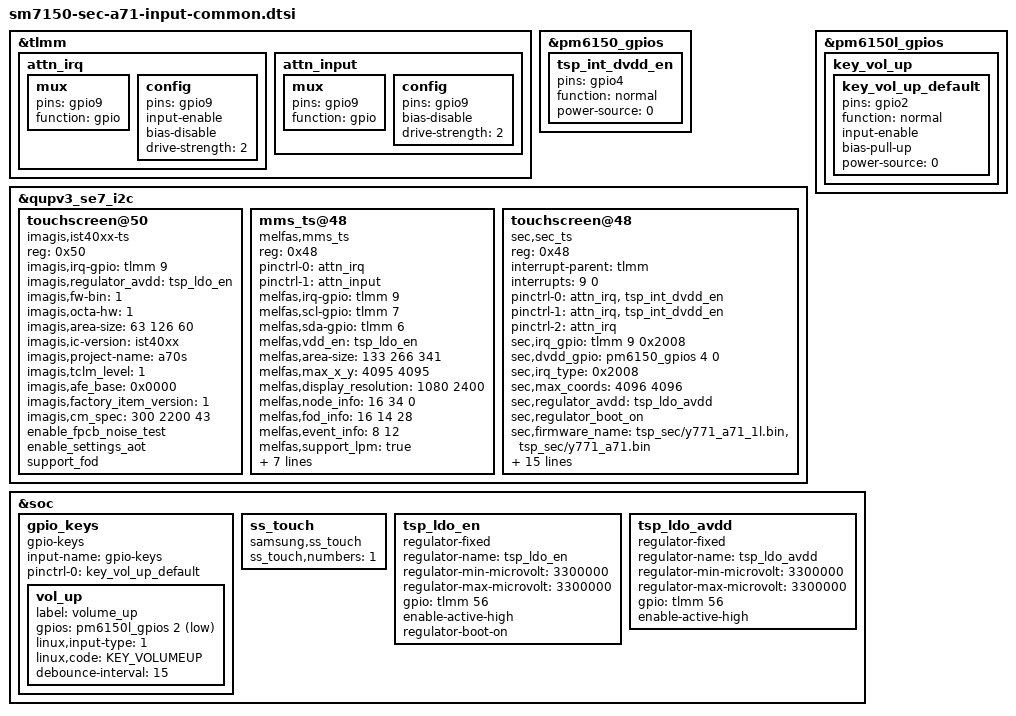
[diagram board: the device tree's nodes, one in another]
/* Copyright (c) 2016-2017, The Linux Foundation. All rights reserved.
 *
 * This program is free software; you can redistribute it and/or modify
 * it under the terms of the GNU General Public License version 2 and
 * only version 2 as published by the Free Software Foundation.
 *
 * This program is distributed in the hope that it will be useful,
 * but WITHOUT ANY WARRANTY; without even the implied warranty of
 * MERCHANTABILITY or FITNESS FOR A PARTICULAR PURPOSE.  See the
 * GNU General Public License for more details.
 */

#include <dt-bindings/input/input.h>

&tlmm {
   attn_irq: attn_irq {
		mux {
			pins = "gpio9";
			function = "gpio";
		};
		
		config {
			pins = "gpio9";
			input-enable;
			bias-disable; /* No PULL */
			drive-strength = <2>;
		};
	};	
	attn_input: attn_input {
		mux {
			pins = "gpio9";
			function = "gpio";
		};
		
		config {
			pins = "gpio9";
			/*input-enable;*/
			bias-disable;
			drive-strength = <2>;
		};
	};
};

&pm6150_gpios {
	tsp_int_dvdd_en: tsp_int_dvdd_en {
		pins = "gpio4";
		function = "normal";
		power-source = <0>;
	};
};


&qupv3_se7_i2c {
	status = "ok";

	touchscreen@50 {
		compatible = "imagis,ist40xx-ts";
		reg = <0x50>;
		imagis,irq-gpio = <&tlmm 9 0>;
		imagis,regulator_avdd = "tsp_ldo_en";
		imagis,fw-bin = <1>;
		imagis,octa-hw = <1>;
		imagis,area-size = <63 126 60>; /* indicator: 24dp~63px navigator:48dp~126px edge:60px | dpi:420*/
		imagis,ic-version = "ist40xx";
		imagis,project-name = "a70s";
		imagis,tclm_level = <1>;
		imagis,afe_base = <0x0000>;
		imagis,factory_item_version = <1>;
		imagis,cm_spec = <300 2200 43>;	/* min, max, gap */
		enable_fpcb_noise_test;
		enable_settings_aot;
		support_fod;
		status = "ok";
	};

	mms_ts@48 {
		compatible = "melfas,mms_ts";
		reg = <0x48>;
		pinctrl-names = "on_state", "off_state";
		pinctrl-0 = <&attn_irq>;
		pinctrl-1 = <&attn_input>;
		melfas,irq-gpio = <&tlmm 9 0>;
		melfas,scl-gpio = <&tlmm 7 0>;
		melfas,sda-gpio = <&tlmm 6 0>;
		melfas,vdd_en = "tsp_ldo_en";
		/*melfas,io_en = "tsp_io";*/
		melfas,area-size = <133 266 341>; /* indicator: 24dp navigator:48dp edge:60px TSP resolution is 4095 x 4095 */
		melfas,max_x_y = <4095 4095>;	/* x & y */
		melfas,display_resolution = <1080 2400>;
		melfas,node_info = <16 34 0>;	/* x & y & key */
		melfas,fod_info = <16 14 28>;	/* tx, rx, vi size */
		melfas,event_info = <8 12>;		/* event format & event size */
		melfas,support_lpm = "true";
		melfas,fw_name = "tsp_melfas/mss100_a70s.bin";
		melfas,ss_touch_num = <1>;
		support_ear_detect_mode;
		enable_settings_aot;
		support_fod;
		support_open_short_test;
		melfas,regulator_boot_on;
		status = "ok";
	};
	
	touchscreen@48 {
		status = "ok";
		compatible = "sec,sec_ts";
		reg = <0x48>;
		interrupt-parent = <&tlmm>;
		interrupts = <9 0>;
		pinctrl-names = "default", "on_state", "off_state";
		pinctrl-0 = <&attn_irq &tsp_int_dvdd_en>;
		pinctrl-1 = <&attn_irq &tsp_int_dvdd_en>;
		pinctrl-2 = <&attn_irq>;
		sec,irq_gpio = <&tlmm 9 0x2008>;
		sec,dvdd_gpio = <&pm6150_gpios 4 0>;    /* tsp_dvdd_en PMIC GPIO 4, tsp_ldo_dvdd regulator */
		sec,irq_type = <0x2008>;
		sec,max_coords = <4096 4096>; /* x y */
		sec,regulator_avdd = "tsp_ldo_avdd";
		sec,regulator_boot_on;
		sec,firmware_name = "tsp_sec/y771_a71_1l.bin", "tsp_sec/y771_a71.bin";
		sec,project_name = "A71", "A715";
		sec,tclm_level = <2>;
		sec,afe_base = <0x0107>;
		support_dex_mode;
		sec,i2c-burstmax = <0xffff>;
		sec,ss_touch_num = <1>;
		enable_settings_aot;
		sec,area-size = <132 266 341>;
		support_ear_detect_mode;
		sync-reportrate-120 = "Y";
		support_fod;
		support_fod_gesture;
		support_open_short_test;
		support_mis_calibration_test;
		sec,bringup = <3>;
	};	
};

/delete-node/&key_vol_up_default;
&pm6150l_gpios {
	key_vol_up {
		key_vol_up_default: key_vol_up_default {
			pins = "gpio2";
			function = "normal";
			input-enable;
			bias-pull-up;
			power-source = <0>;
		};
	};
};

&soc {
	/delete-node/gpio_keys;
	gpio_keys {
		status = "ok";
		compatible = "gpio-keys";
		input-name = "gpio-keys";

		pinctrl-names = "default";
		pinctrl-0 = <&key_vol_up_default>;

		vol_up {
			label = "volume_up";
			gpios = <&pm6150l_gpios 2 0x1>;
			linux,input-type = <1>;
			linux,code = <KEY_VOLUMEUP>;
			debounce-interval = <15>;
		};
	};

	ss_touch {
		compatible = "samsung,ss_touch";
		ss_touch,numbers = <1>;
	};

	tsp_ldo_en {
		compatible = "regulator-fixed";
		regulator-name = "tsp_ldo_en";
		regulator-min-microvolt = <3300000>;
		regulator-max-microvolt = <3300000>;
		gpio = <&tlmm 56 0>;
		enable-active-high;
		regulator-boot-on;
	};
	
	tsp_ldo_avdd {
		compatible = "regulator-fixed";
		regulator-name = "tsp_ldo_avdd";
		regulator-min-microvolt = <3300000>;
		regulator-max-microvolt = <3300000>;
		gpio = <&tlmm 56 0>;
		enable-active-high;
	};
};
